AUTOSAR XML (schema 00048)
package /AUTOSAR_NvM/PortInterfaces
  6 x client server interface, all with is-service=true:
    NvMAdmin
      operation SetBlockProtection: possible-error=NvMAdmin/E_NOT_OK
        arg ProtectionEnabled: type=boolean, direction=IN
      error E_NOT_OK: error-code=1
    NvMMirror
      operation ReadRamBlockFromNvM: possible-error=NvMMirror/E_NOT_OK
        arg SrcPtr: type=NvM_Rb_VoidPtr, direction=IN
      operation WriteRamBlockToNvM: possible-error=NvMMirror/E_NOT_OK
        arg DstPtr: type=NvM_Rb_VoidPtr, direction=IN
      error E_NOT_OK: error-code=1
    NvMNotifyInitBlock
      operation InitBlock: possible-error=NvMNotifyInitBlock/E_NOT_OK
      error E_NOT_OK: error-code=1
    NvMNotifyJobFinished
      operation JobFinished: possible-error=NvMNotifyJobFinished/E_NOT_OK
        arg ServiceId: type=uint8, direction=IN
        arg JobResult: type=NvM_RequestResultType, direction=IN
      error E_NOT_OK: error-code=1
    NvMRbNotifyJobStarted
      operation JobStarted
        arg ServiceId: type=uint8, direction=IN
    NvMService
      12 x operation, all with possible-error=NvMService/E_NOT_OK:
        EraseBlock
        GetDataIndex
          arg DataIndexPtr: type=uint8, direction=OUT
        GetErrorStatus
          arg RequestResultPtr: type=NvM_RequestResultType, direction=OUT
        InvalidateNvBlock
        ReadBlock
          arg DstPtr: type=NvM_Rb_VoidPtr, direction=IN
        ReadPRAMBlock
        RestoreBlockDefaults
          arg DstPtr: type=NvM_Rb_VoidPtr, direction=IN
        RestorePRAMBlockDefaults
        SetDataIndex
          arg DataIndex: type=uint8, direction=IN
        SetRamBlockStatus
          arg BlockChanged: type=boolean, direction=IN
        WriteBlock
          arg SrcPtr: type=NvM_Rb_ConstVoidPtr, direction=IN
        WritePRAMBlock
      error E_NOT_OK: error-code=1
package /AUTOSAR_NvM/SwcImplementations
  swc implementation NvM: programming-language=C, swc-bsw-mapping=NvM, vendor-id=6, behavior=NVRAMManager
    code-descriptors:
      code CodeDescriptor: artifact-descriptors=autosar-engineering-object={short-label=ArEngObj, category=SWSRC}
package /AUTOSAR_NvM/SwComponentTypes
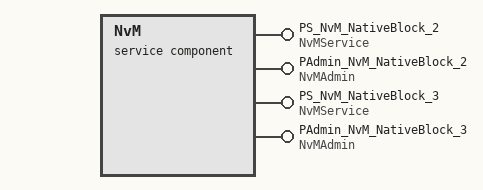
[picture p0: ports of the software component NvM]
  service sw component type NvM
    4 x provide port:
      PS_NvM_NativeBlock_2: provided-interface=NvMService
        provided-com-specs:
          operation=EraseBlock, queue-length=1
          operation=GetDataIndex, queue-length=1
          operation=GetErrorStatus, queue-length=1
          operation=InvalidateNvBlock, queue-length=1
          operation=ReadBlock, queue-length=1
          operation=ReadPRAMBlock, queue-length=1
          operation=RestoreBlockDefaults, queue-length=1
          operation=RestorePRAMBlockDefaults, queue-length=1
          operation=SetDataIndex, queue-length=1
          operation=SetRamBlockStatus, queue-length=1
          operation=WriteBlock, queue-length=1
          operation=WritePRAMBlock, queue-length=1
      PAdmin_NvM_NativeBlock_2: server-com-spec{operation=SetBlockProtection, queue-length=1}, provided-interface=NvMAdmin
      PS_NvM_NativeBlock_3: provided-interface=NvMService
        provided-com-specs:
          operation=EraseBlock, queue-length=1
          operation=GetDataIndex, queue-length=1
          operation=GetErrorStatus, queue-length=1
          operation=InvalidateNvBlock, queue-length=1
          operation=ReadBlock, queue-length=1
          operation=ReadPRAMBlock, queue-length=1
          operation=RestoreBlockDefaults, queue-length=1
          operation=RestorePRAMBlockDefaults, queue-length=1
          operation=SetDataIndex, queue-length=1
          operation=SetRamBlockStatus, queue-length=1
          operation=WriteBlock, queue-length=1
          operation=WritePRAMBlock, queue-length=1
      PAdmin_NvM_NativeBlock_3: server-com-spec{operation=SetBlockProtection, queue-length=1}, provided-interface=NvMAdmin
    behavior NVRAMManager
      26 x operation invoked event:
        EENB_NvM_NativeBlock_2: start-on-event=EraseNvBlock, operation=PS_NvM_NativeBlock_2.EraseBlock
        EGDI_NvM_NativeBlock_2: start-on-event=GetDataIndex, operation=PS_NvM_NativeBlock_2.GetDataIndex
        EGES_NvM_NativeBlock_2: start-on-event=GetErrorStatus, operation=PS_NvM_NativeBlock_2.GetErrorStatus
        EINB_NvM_NativeBlock_2: start-on-event=InvalidateNvBlock, operation=PS_NvM_NativeBlock_2.InvalidateNvBlock
        ERBL_NvM_NativeBlock_2: start-on-event=ReadBlock, operation=PS_NvM_NativeBlock_2.ReadBlock
        ERPBL_NvM_NativeBlock_2: start-on-event=ReadPRAMBlock, operation=PS_NvM_NativeBlock_2.ReadPRAMBlock
        ERBD_NvM_NativeBlock_2: start-on-event=RestoreBlockDefaults, operation=PS_NvM_NativeBlock_2.RestoreBlockDefaults
        ERPBD_NvM_NativeBlock_2: start-on-event=RestorePRAMBlockDefaults, operation=PS_NvM_NativeBlock_2.RestorePRAMBlockDefaults
        ESBP_NvM_NativeBlock_2: start-on-event=SetBlockProtection, operation=PAdmin_NvM_NativeBlock_2.SetBlockProtection
        ESDI_NvM_NativeBlock_2: start-on-event=SetDataIndex, operation=PS_NvM_NativeBlock_2.SetDataIndex
        ESRS_NvM_NativeBlock_2: start-on-event=SetRamBlockStatus, operation=PS_NvM_NativeBlock_2.SetRamBlockStatus
        EWBL_NvM_NativeBlock_2: start-on-event=WriteBlock, operation=PS_NvM_NativeBlock_2.WriteBlock
        EWPBL_NvM_NativeBlock_2: start-on-event=WritePRAMBlock, operation=PS_NvM_NativeBlock_2.WritePRAMBlock
        EENB_NvM_NativeBlock_3: start-on-event=EraseNvBlock, operation=PS_NvM_NativeBlock_3.EraseBlock
        EGDI_NvM_NativeBlock_3: start-on-event=GetDataIndex, operation=PS_NvM_NativeBlock_3.GetDataIndex
        EGES_NvM_NativeBlock_3: start-on-event=GetErrorStatus, operation=PS_NvM_NativeBlock_3.GetErrorStatus
        EINB_NvM_NativeBlock_3: start-on-event=InvalidateNvBlock, operation=PS_NvM_NativeBlock_3.InvalidateNvBlock
        ERBL_NvM_NativeBlock_3: start-on-event=ReadBlock, operation=PS_NvM_NativeBlock_3.ReadBlock
        ERPBL_NvM_NativeBlock_3: start-on-event=ReadPRAMBlock, operation=PS_NvM_NativeBlock_3.ReadPRAMBlock
        ERBD_NvM_NativeBlock_3: start-on-event=RestoreBlockDefaults, operation=PS_NvM_NativeBlock_3.RestoreBlockDefaults
        ERPBD_NvM_NativeBlock_3: start-on-event=RestorePRAMBlockDefaults, operation=PS_NvM_NativeBlock_3.RestorePRAMBlockDefaults
        ESBP_NvM_NativeBlock_3: start-on-event=SetBlockProtection, operation=PAdmin_NvM_NativeBlock_3.SetBlockProtection
        ESDI_NvM_NativeBlock_3: start-on-event=SetDataIndex, operation=PS_NvM_NativeBlock_3.SetDataIndex
        ESRS_NvM_NativeBlock_3: start-on-event=SetRamBlockStatus, operation=PS_NvM_NativeBlock_3.SetRamBlockStatus
        EWBL_NvM_NativeBlock_3: start-on-event=WriteBlock, operation=PS_NvM_NativeBlock_3.WriteBlock
        EWPBL_NvM_NativeBlock_3: start-on-event=WritePRAMBlock, operation=PS_NvM_NativeBlock_3.WritePRAMBlock
      port-api-options:
        {enable-take-address=false, indirect-api=false, port-defined-argument-value{value=NvMConf_NvMBlockDescriptor_NvM_NativeBlock_2, value-type=NvM_BlockIdType}, port=PS_NvM_NativeBlock_2}
        {enable-take-address=false, indirect-api=false, port-defined-argument-value{value=NvMConf_NvMBlockDescriptor_NvM_NativeBlock_2, value-type=NvM_BlockIdType}, port=PAdmin_NvM_NativeBlock_2}
        {enable-take-address=false, indirect-api=false, port-defined-argument-value{value=NvMConf_NvMBlockDescriptor_NvM_NativeBlock_3, value-type=NvM_BlockIdType}, port=PS_NvM_NativeBlock_3}
        {enable-take-address=false, indirect-api=false, port-defined-argument-value{value=NvMConf_NvMBlockDescriptor_NvM_NativeBlock_3, value-type=NvM_BlockIdType}, port=PAdmin_NvM_NativeBlock_3}
      14 x runnable:
        EraseNvBlock: runnable-entity-argument=symbol=BlockId, can-be-invoked-concurrently=true, symbol=NvM_EraseNvBlock
        GetDataIndex: arguments=[symbol=BlockId, symbol=DataIndexPtr], can-be-invoked-concurrently=true, symbol=NvM_GetDataIndex
        GetErrorStatus: arguments=[symbol=BlockId, symbol=RequestResultPtr], can-be-invoked-concurrently=true, symbol=NvM_GetErrorStatus
        InvalidateNvBlock: runnable-entity-argument=symbol=BlockId, can-be-invoked-concurrently=true, symbol=NvM_InvalidateNvBlock
        ReadBlock: arguments=[symbol=BlockId, symbol=NvM_DstPtr], can-be-invoked-concurrently=true, symbol=NvM_ReadBlock
        ReadPRAMBlock: runnable-entity-argument=symbol=BlockId, can-be-invoked-concurrently=true, symbol=NvM_ReadPRAMBlock
        RestoreBlockDefaults: arguments=[symbol=BlockId, symbol=NvM_DstPtr], can-be-invoked-concurrently=true, symbol=NvM_RestoreBlockDefaults
        RestorePRAMBlockDefaults: runnable-entity-argument=symbol=BlockId, can-be-invoked-concurrently=true, symbol=NvM_RestorePRAMBlockDefaults
        SetBlockProtection: arguments=[symbol=BlockId, symbol=ProtectionEnabled], can-be-invoked-concurrently=true, symbol=NvM_SetBlockProtection
        SetDataIndex: arguments=[symbol=BlockId, symbol=DataIndex], can-be-invoked-concurrently=true, symbol=NvM_SetDataIndex
        SetRamBlockStatus: arguments=[symbol=BlockId, symbol=BlockChanged], can-be-invoked-concurrently=true, symbol=NvM_SetRamBlockStatus
        WriteBlock: arguments=[symbol=BlockId, symbol=NvM_SrcPtr], can-be-invoked-concurrently=true, symbol=NvM_WriteBlock
        WritePRAMBlock: runnable-entity-argument=symbol=BlockId, can-be-invoked-concurrently=true, symbol=NvM_WritePRAMBlock
        MainFunction: symbol=NvM_MainFunction
